AUTOSAR XML (schema 4-0-3)
standard types defined: Boolean, UInt16
package /AUTOSAR_Platform/DataConstrs
  range DC_Boolean: raw 0..1
  range DC_UInt16: raw 0..65535
package /PATAC/MSM/ComponentTypes
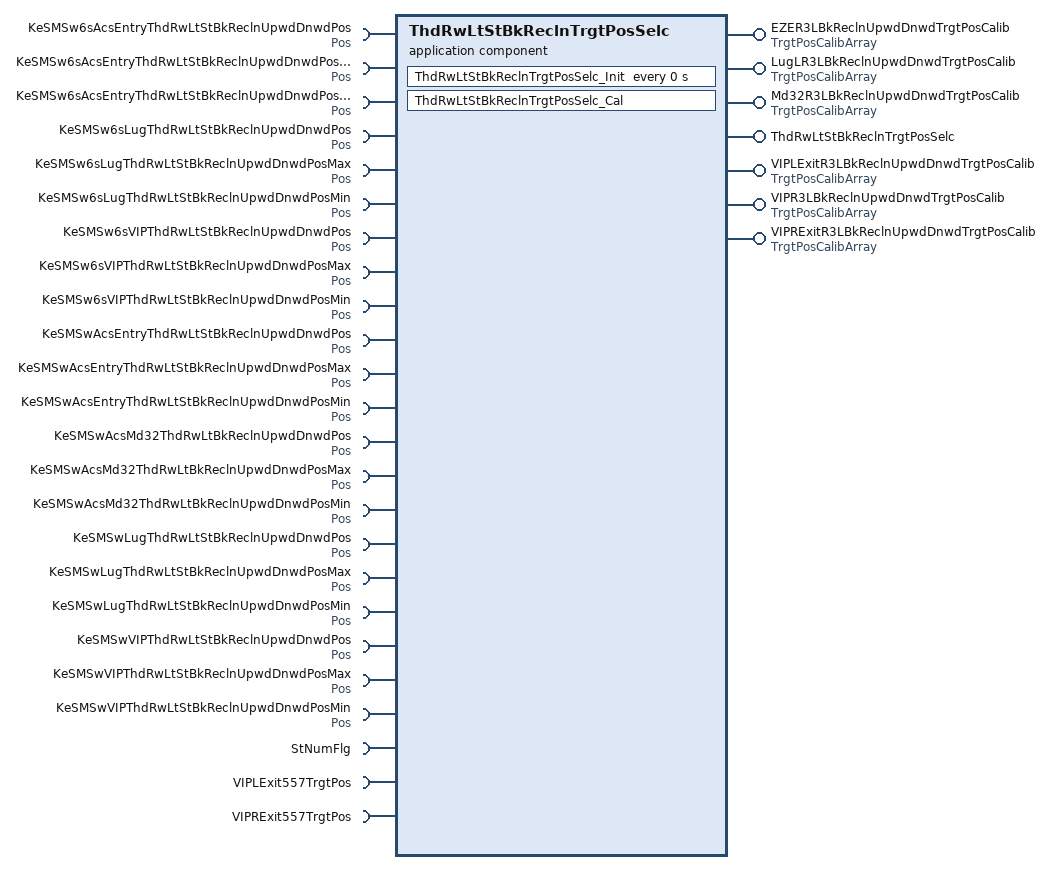
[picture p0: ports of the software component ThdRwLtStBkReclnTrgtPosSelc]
  application sw component type ThdRwLtStBkReclnTrgtPosSelc
    7 x provide port:
      EZER3LBkReclnUpwdDnwdTrgtPosCalib: nonqueued-sender-com-spec{data-element=TrgtPosArray, init-value=[4095, 4095, 4095]}, provided-interface=TrgtPosCalibArray
      LugLR3LBkReclnUpwdDnwdTrgtPosCalib: nonqueued-sender-com-spec{data-element=TrgtPosArray, init-value=[4095, 4095, 4095]}, provided-interface=TrgtPosCalibArray
      Md32R3LBkReclnUpwdDnwdTrgtPosCalib: nonqueued-sender-com-spec{data-element=TrgtPosArray, init-value=[4095, 4095, 4095]}, provided-interface=TrgtPosCalibArray
      ThdRwLtStBkReclnTrgtPosSelc: server-com-spec{operation=Cal, queue-length=1}, provided-interface=ThdRwLtStBkReclnTrgtPosSelc
      VIPLExitR3LBkReclnUpwdDnwdTrgtPosCalib: nonqueued-sender-com-spec{data-element=TrgtPosArray, init-value=[4095, 4095, 4095]}, provided-interface=TrgtPosCalibArray
      VIPR3LBkReclnUpwdDnwdTrgtPosCalib: nonqueued-sender-com-spec{data-element=TrgtPosArray, init-value=[4095, 4095, 4095]}, provided-interface=TrgtPosCalibArray
      VIPRExitR3LBkReclnUpwdDnwdTrgtPosCalib: nonqueued-sender-com-spec{data-element=TrgtPosArray, init-value=[4095, 4095, 4095]}, provided-interface=TrgtPosCalibArray
    24 x require port:
      KeSMSw6sAcsEntryThdRwLtStBkReclnUpwdDnwdPos: parameter-require-com-spec{init-value=2080, parameter=Val}, required-interface=Pos
      KeSMSw6sAcsEntryThdRwLtStBkReclnUpwdDnwdPosMax: parameter-require-com-spec{init-value=2095, parameter=Val}, required-interface=Pos
      KeSMSw6sAcsEntryThdRwLtStBkReclnUpwdDnwdPosMin: parameter-require-com-spec{init-value=0, parameter=Val}, required-interface=Pos
      KeSMSw6sLugThdRwLtStBkReclnUpwdDnwdPos: parameter-require-com-spec{init-value=0, parameter=Val}, required-interface=Pos
      KeSMSw6sLugThdRwLtStBkReclnUpwdDnwdPosMax: parameter-require-com-spec{init-value=0, parameter=Val}, required-interface=Pos
      KeSMSw6sLugThdRwLtStBkReclnUpwdDnwdPosMin: parameter-require-com-spec{init-value=0, parameter=Val}, required-interface=Pos
      KeSMSw6sVIPThdRwLtStBkReclnUpwdDnwdPos: parameter-require-com-spec{init-value=0, parameter=Val}, required-interface=Pos
      KeSMSw6sVIPThdRwLtStBkReclnUpwdDnwdPosMax: parameter-require-com-spec{init-value=0, parameter=Val}, required-interface=Pos
      KeSMSw6sVIPThdRwLtStBkReclnUpwdDnwdPosMin: parameter-require-com-spec{init-value=0, parameter=Val}, required-interface=Pos
      KeSMSwAcsEntryThdRwLtStBkReclnUpwdDnwdPos: parameter-require-com-spec{init-value=2080, parameter=Val}, required-interface=Pos
      KeSMSwAcsEntryThdRwLtStBkReclnUpwdDnwdPosMax: parameter-require-com-spec{init-value=2095, parameter=Val}, required-interface=Pos
      KeSMSwAcsEntryThdRwLtStBkReclnUpwdDnwdPosMin: parameter-require-com-spec{init-value=0, parameter=Val}, required-interface=Pos
      KeSMSwAcsMd32ThdRwLtBkReclnUpwdDnwdPos: parameter-require-com-spec{init-value=2080, parameter=Val}, required-interface=Pos
      KeSMSwAcsMd32ThdRwLtBkReclnUpwdDnwdPosMax: parameter-require-com-spec{init-value=2080, parameter=Val}, required-interface=Pos
      KeSMSwAcsMd32ThdRwLtBkReclnUpwdDnwdPosMin: parameter-require-com-spec{init-value=2080, parameter=Val}, required-interface=Pos
      KeSMSwLugThdRwLtStBkReclnUpwdDnwdPos: parameter-require-com-spec{init-value=0, parameter=Val}, required-interface=Pos
      KeSMSwLugThdRwLtStBkReclnUpwdDnwdPosMax: parameter-require-com-spec{init-value=0, parameter=Val}, required-interface=Pos
      KeSMSwLugThdRwLtStBkReclnUpwdDnwdPosMin: parameter-require-com-spec{init-value=0, parameter=Val}, required-interface=Pos
      KeSMSwVIPThdRwLtStBkReclnUpwdDnwdPos: parameter-require-com-spec{init-value=0, parameter=Val}, required-interface=Pos
      KeSMSwVIPThdRwLtStBkReclnUpwdDnwdPosMax: parameter-require-com-spec{init-value=0, parameter=Val}, required-interface=Pos
      KeSMSwVIPThdRwLtStBkReclnUpwdDnwdPosMin: parameter-require-com-spec{init-value=0, parameter=Val}, required-interface=Pos
      StNumFlg: required-interface=StNumFlg
        required-com-specs:
          data-element=Is4s, filter=data-filter-type=ALWAYS, init-value=0
          data-element=Is6s, filter=data-filter-type=ALWAYS, init-value=0
          data-element=Is6s7s, filter=data-filter-type=ALWAYS, init-value=0
          data-element=Is7s, filter=data-filter-type=ALWAYS, init-value=0
      VIPLExit557TrgtPos: required-com-specs=[VIPLExit557TrgtPos/Get, VIPLExit557TrgtPos/Set], required-interface=VIPLExit557TrgtPos
      VIPRExit557TrgtPos: required-com-specs=[VIPRExit557TrgtPos/Get, VIPRExit557TrgtPos/Set], required-interface=VIPRExit557TrgtPos
    behavior ThdRwLtStBkReclnTrgtPosSelc_InternalBehavior
      operation invoked event OIT_ThdRwLtStBkReclnTrgtPosSelc_Cal_ThdRwLtStBkReclnTrgtPosSelc_Cal: start-on-event=ThdRwLtStBkReclnTrgtPosSelc_Cal, operation=ThdRwLtStBkReclnTrgtPosSelc.Cal
      timing event ThdRwLtStBkReclnTrgtPosSelc_InitEvent: start-on-event=ThdRwLtStBkReclnTrgtPosSelc_Init, period=0
      runnable ThdRwLtStBkReclnTrgtPosSelc_Cal
        data-receive-point-by-arguments:
          4 x access:
            REC_StNumFlg_Is4s: accessed-variable=StNumFlg.Is4s
            REC_StNumFlg_Is6s: accessed-variable=StNumFlg.Is6s
            REC_StNumFlg_Is6s7s: accessed-variable=StNumFlg.Is6s7s
            REC_StNumFlg_Is7s: accessed-variable=StNumFlg.Is7s
        data-send-points:
          6 x access:
            SEND_EZER3LBkReclnUpwdDnwdTrgtPosCalib_TrgtPosArray: accessed-variable=EZER3LBkReclnUpwdDnwdTrgtPosCalib.TrgtPosArray
            SEND_LugLR3LBkReclnUpwdDnwdTrgtPosCalib_TrgtPosArray: accessed-variable=LugLR3LBkReclnUpwdDnwdTrgtPosCalib.TrgtPosArray
            SEND_Md32R3LBkReclnUpwdDnwdTrgtPosCalib_TrgtPosArray: accessed-variable=Md32R3LBkReclnUpwdDnwdTrgtPosCalib.TrgtPosArray
            SEND_VIPLExitR3LBkReclnUpwdDnwdTrgtPosCalib_TrgtPosArray: accessed-variable=VIPLExitR3LBkReclnUpwdDnwdTrgtPosCalib.TrgtPosArray
            SEND_VIPR3LBkReclnUpwdDnwdTrgtPosCalib_TrgtPosArray: accessed-variable=VIPR3LBkReclnUpwdDnwdTrgtPosCalib.TrgtPosArray
            SEND_VIPRExitR3LBkReclnUpwdDnwdTrgtPosCalib_TrgtPosArray: accessed-variable=VIPRExitR3LBkReclnUpwdDnwdTrgtPosCalib.TrgtPosArray
        21 x parameter access:
          PA_KeSMSw6sAcsEntryThdRwLtStBkReclnUpwdDnwdPos_Val: accessed-parameter=KeSMSw6sAcsEntryThdRwLtStBkReclnUpwdDnwdPos.Val
          PA_KeSMSw6sAcsEntryThdRwLtStBkReclnUpwdDnwdPosMax_Val: accessed-parameter=KeSMSw6sAcsEntryThdRwLtStBkReclnUpwdDnwdPosMax.Val
          PA_KeSMSw6sAcsEntryThdRwLtStBkReclnUpwdDnwdPosMin_Val: accessed-parameter=KeSMSw6sAcsEntryThdRwLtStBkReclnUpwdDnwdPosMin.Val
          PA_KeSMSw6sLugThdRwLtStBkReclnUpwdDnwdPos_Val: accessed-parameter=KeSMSw6sLugThdRwLtStBkReclnUpwdDnwdPos.Val
          PA_KeSMSw6sLugThdRwLtStBkReclnUpwdDnwdPosMax_Val: accessed-parameter=KeSMSw6sLugThdRwLtStBkReclnUpwdDnwdPosMax.Val
          PA_KeSMSw6sLugThdRwLtStBkReclnUpwdDnwdPosMin_Val: accessed-parameter=KeSMSw6sLugThdRwLtStBkReclnUpwdDnwdPosMin.Val
          PA_KeSMSw6sVIPThdRwLtStBkReclnUpwdDnwdPos_Val: accessed-parameter=KeSMSw6sVIPThdRwLtStBkReclnUpwdDnwdPos.Val
          PA_KeSMSw6sVIPThdRwLtStBkReclnUpwdDnwdPosMax_Val: accessed-parameter=KeSMSw6sVIPThdRwLtStBkReclnUpwdDnwdPosMax.Val
          PA_KeSMSw6sVIPThdRwLtStBkReclnUpwdDnwdPosMin_Val: accessed-parameter=KeSMSw6sVIPThdRwLtStBkReclnUpwdDnwdPosMin.Val
          PA_KeSMSwAcsEntryThdRwLtStBkReclnUpwdDnwdPos_Val: accessed-parameter=KeSMSwAcsEntryThdRwLtStBkReclnUpwdDnwdPos.Val
          PA_KeSMSwAcsEntryThdRwLtStBkReclnUpwdDnwdPosMax_Val: accessed-parameter=KeSMSwAcsEntryThdRwLtStBkReclnUpwdDnwdPosMax.Val
          PA_KeSMSwAcsEntryThdRwLtStBkReclnUpwdDnwdPosMin_Val: accessed-parameter=KeSMSwAcsEntryThdRwLtStBkReclnUpwdDnwdPosMin.Val
          PA_KeSMSwAcsMd32ThdRwLtBkReclnUpwdDnwdPos_Val: accessed-parameter=KeSMSwAcsMd32ThdRwLtBkReclnUpwdDnwdPos.Val
          PA_KeSMSwAcsMd32ThdRwLtBkReclnUpwdDnwdPosMax_Val: accessed-parameter=KeSMSwAcsMd32ThdRwLtBkReclnUpwdDnwdPosMax.Val
          PA_KeSMSwAcsMd32ThdRwLtBkReclnUpwdDnwdPosMin_Val: accessed-parameter=KeSMSwAcsMd32ThdRwLtBkReclnUpwdDnwdPosMin.Val
          PA_KeSMSwLugThdRwLtStBkReclnUpwdDnwdPos_Val: accessed-parameter=KeSMSwLugThdRwLtStBkReclnUpwdDnwdPos.Val
          PA_KeSMSwLugThdRwLtStBkReclnUpwdDnwdPosMax_Val: accessed-parameter=KeSMSwLugThdRwLtStBkReclnUpwdDnwdPosMax.Val
          PA_KeSMSwLugThdRwLtStBkReclnUpwdDnwdPosMin_Val: accessed-parameter=KeSMSwLugThdRwLtStBkReclnUpwdDnwdPosMin.Val
          PA_KeSMSwVIPThdRwLtStBkReclnUpwdDnwdPos_Val: accessed-parameter=KeSMSwVIPThdRwLtStBkReclnUpwdDnwdPos.Val
          PA_KeSMSwVIPThdRwLtStBkReclnUpwdDnwdPosMax_Val: accessed-parameter=KeSMSwVIPThdRwLtStBkReclnUpwdDnwdPosMax.Val
          PA_KeSMSwVIPThdRwLtStBkReclnUpwdDnwdPosMin_Val: accessed-parameter=KeSMSwVIPThdRwLtStBkReclnUpwdDnwdPosMin.Val
        sync call SC_VIPLExit557TrgtPos_Get: operation=VIPLExit557TrgtPos.Get, timeout=0
        sync call SC_VIPRExit557TrgtPos_Get: operation=VIPRExit557TrgtPos.Get, timeout=0
      runnable ThdRwLtStBkReclnTrgtPosSelc_Init
        21 x parameter access:
          PA_KeSMSw6sAcsEntryThdRwLtStBkReclnUpwdDnwdPos_Val: accessed-parameter=KeSMSw6sAcsEntryThdRwLtStBkReclnUpwdDnwdPos.Val
          PA_KeSMSw6sAcsEntryThdRwLtStBkReclnUpwdDnwdPosMax_Val: accessed-parameter=KeSMSw6sAcsEntryThdRwLtStBkReclnUpwdDnwdPosMax.Val
          PA_KeSMSw6sAcsEntryThdRwLtStBkReclnUpwdDnwdPosMin_Val: accessed-parameter=KeSMSw6sAcsEntryThdRwLtStBkReclnUpwdDnwdPosMin.Val
          PA_KeSMSw6sLugThdRwLtStBkReclnUpwdDnwdPos_Val: accessed-parameter=KeSMSw6sLugThdRwLtStBkReclnUpwdDnwdPos.Val
          PA_KeSMSw6sLugThdRwLtStBkReclnUpwdDnwdPosMax_Val: accessed-parameter=KeSMSw6sLugThdRwLtStBkReclnUpwdDnwdPosMax.Val
          PA_KeSMSw6sLugThdRwLtStBkReclnUpwdDnwdPosMin_Val: accessed-parameter=KeSMSw6sLugThdRwLtStBkReclnUpwdDnwdPosMin.Val
          PA_KeSMSw6sVIPThdRwLtStBkReclnUpwdDnwdPos_Val: accessed-parameter=KeSMSw6sVIPThdRwLtStBkReclnUpwdDnwdPos.Val
          PA_KeSMSw6sVIPThdRwLtStBkReclnUpwdDnwdPosMax_Val: accessed-parameter=KeSMSw6sVIPThdRwLtStBkReclnUpwdDnwdPosMax.Val
          PA_KeSMSw6sVIPThdRwLtStBkReclnUpwdDnwdPosMin_Val: accessed-parameter=KeSMSw6sVIPThdRwLtStBkReclnUpwdDnwdPosMin.Val
          PA_KeSMSwAcsEntryThdRwLtStBkReclnUpwdDnwdPos_Val: accessed-parameter=KeSMSwAcsEntryThdRwLtStBkReclnUpwdDnwdPos.Val
          PA_KeSMSwAcsEntryThdRwLtStBkReclnUpwdDnwdPosMax_Val: accessed-parameter=KeSMSwAcsEntryThdRwLtStBkReclnUpwdDnwdPosMax.Val
          PA_KeSMSwAcsEntryThdRwLtStBkReclnUpwdDnwdPosMin_Val: accessed-parameter=KeSMSwAcsEntryThdRwLtStBkReclnUpwdDnwdPosMin.Val
          PA_KeSMSwAcsMd32ThdRwLtBkReclnUpwdDnwdPos_Val: accessed-parameter=KeSMSwAcsMd32ThdRwLtBkReclnUpwdDnwdPos.Val
          PA_KeSMSwAcsMd32ThdRwLtBkReclnUpwdDnwdPosMax_Val: accessed-parameter=KeSMSwAcsMd32ThdRwLtBkReclnUpwdDnwdPosMax.Val
          PA_KeSMSwAcsMd32ThdRwLtBkReclnUpwdDnwdPosMin_Val: accessed-parameter=KeSMSwAcsMd32ThdRwLtBkReclnUpwdDnwdPosMin.Val
          PA_KeSMSwLugThdRwLtStBkReclnUpwdDnwdPos_Val: accessed-parameter=KeSMSwLugThdRwLtStBkReclnUpwdDnwdPos.Val
          PA_KeSMSwLugThdRwLtStBkReclnUpwdDnwdPosMax_Val: accessed-parameter=KeSMSwLugThdRwLtStBkReclnUpwdDnwdPosMax.Val
          PA_KeSMSwLugThdRwLtStBkReclnUpwdDnwdPosMin_Val: accessed-parameter=KeSMSwLugThdRwLtStBkReclnUpwdDnwdPosMin.Val
          PA_KeSMSwVIPThdRwLtStBkReclnUpwdDnwdPos_Val: accessed-parameter=KeSMSwVIPThdRwLtStBkReclnUpwdDnwdPos.Val
          PA_KeSMSwVIPThdRwLtStBkReclnUpwdDnwdPosMax_Val: accessed-parameter=KeSMSwVIPThdRwLtStBkReclnUpwdDnwdPosMax.Val
          PA_KeSMSwVIPThdRwLtStBkReclnUpwdDnwdPosMin_Val: accessed-parameter=KeSMSwVIPThdRwLtStBkReclnUpwdDnwdPosMin.Val
  swc implementation ThdRwLtStBkReclnTrgtPosSelc_Implementation: behavior=ThdRwLtStBkReclnTrgtPosSelc_InternalBehavior
    code-descriptors:
      code Default: artifact-descriptors=autosar-engineering-object={short-label=Default, category=SWSRC}
package /PATAC/MSM/ModeAdjust/CalPortInterface
  parameter interface Pos
    parameter data prototype Val: sw-calibration-access=READ-WRITE, type=UInt16
package /PATAC/MSM/ModeAdjust/DataType
  impl type TrgtPosCalibArray: category=ARRAY, sw-calibration-access=READ-ONLY, type-emitter=RTE  # 0:pos 1:max 2:min
    element Element: array-size=3, array-size-semantics=FIXED-SIZE, implementation-data-type=UInt16, invalid-value=0
package /PATAC/MSM/ModeAdjust/PortInterface
  client server interface ThdRwLtStBkReclnTrgtPosSelc
    operation Cal
  client server interface VIPLExit557TrgtPos
    operation Get
      7 x arg, all with type=UInt16, direction=OUT, server-argument-impl-policy=USE-ARGUMENT-TYPE:
        SecRwLtStBkReclnTrgtPos
        SecRwLtStZeroTrgtPos
        SecRwLtStLgrstUpwdDnwdTrgtPos
        SecRwLtStLgrstInwdOtwdTrgtPos
        ThdRwLtStBkReclnTrgtPos
        ThdRwLtStFwdBkwdTrgtPos
        SecRwLtStFwdBkwdTrgtPos
    operation Set
  client server interface VIPRExit557TrgtPos
    operation Get
      11 x arg, all with type=UInt16, direction=OUT, server-argument-impl-policy=USE-ARGUMENT-TYPE:
        SecRwRtStBkReclnTrgtPos
        SecRwRtStZeroTrgtPos
        SecRwRtStLgrstUpwdDnwdTrgtPos
        SecRwRtStLgrstInwdOtwdTrgtPos
        ThdRwLtStBkReclnTrgtPos
        ThdRwLtStFwdBkwdTrgtPos
        ThdRwRtStBkReclnTrgtPos
        ThdRwRtStFwdBkwdTrgtPos
        PassStBkReclnTrgtPos
        PassStFwdBkwdTrgtPos
        SecRwRtStFwdBkwdTrgtPos
    operation Set
  sender receiver interface StNumFlg
    4 x data, all with type=Boolean:
      Is4s
      Is6s
      Is6s7s
      Is7s
    invalidation-policys:
      data-element=Is4s, handle-invalid=DONT-INVALIDATE
      data-element=Is6s, handle-invalid=DONT-INVALIDATE
      data-element=Is6s7s, handle-invalid=DONT-INVALIDATE
      data-element=Is7s, handle-invalid=DONT-INVALIDATE
  sender receiver interface TrgtPosCalibArray: invalidation-policy{data-element=TrgtPosArray, handle-invalid=DONT-INVALIDATE}
    data TrgtPosArray: type=TrgtPosCalibArray  # 0:Pos 1:Max 2:Min
